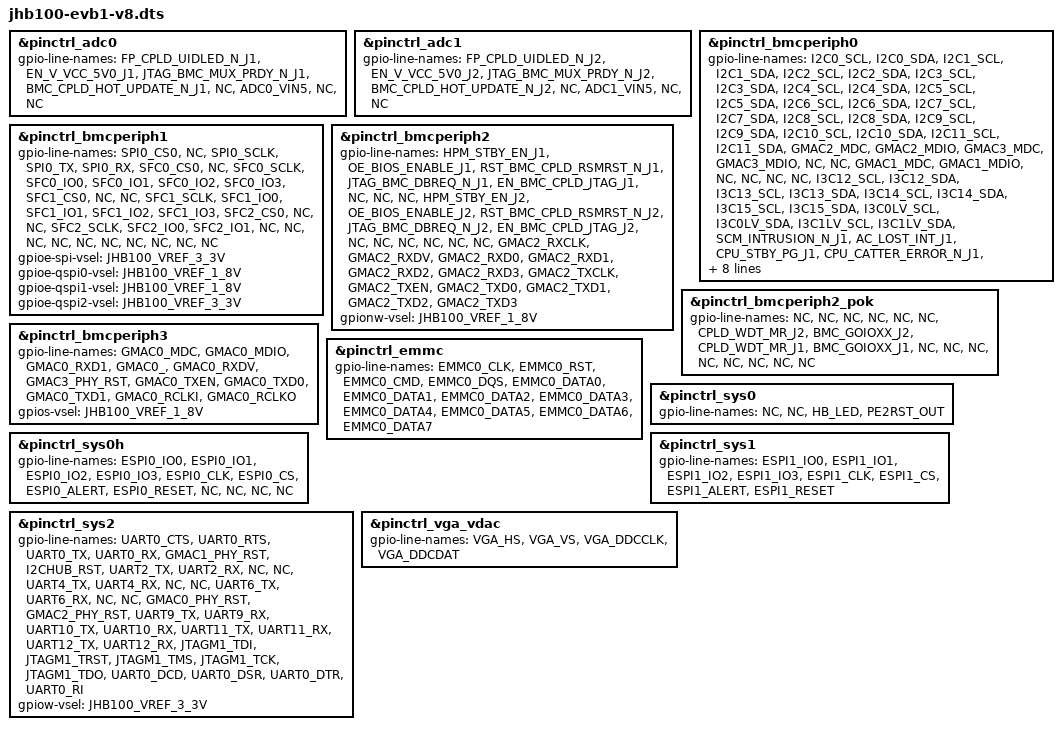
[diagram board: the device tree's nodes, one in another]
// SPDX-License-Identifier: GPL-2.0 OR MIT
/*
 * Copyright (c) 2025 StarFive Technology Co., Ltd.
 */

#include "jhb100-evb1.dtsi"
#include "jhb100-evb1-ethernet.dtsi"
#include "jhb100-evb1-sib2.dtsi"

&pinctrl_adc0 {
	gpio-line-names =
		"FP_CPLD_UIDLED_N_J1", "EN_V_VCC_5V0_J1",		/* GPIOG0-1 */
		"JTAG_BMC_MUX_PRDY_N_J1", "BMC_CPLD_HOT_UPDATE_N_J1",	/* GPIOG2-3 */
		"NC", "ADC0_VIN5", "NC", "NC";				/* GPIOG4-7 */
};

&pinctrl_adc1 {
	gpio-line-names =
		"FP_CPLD_UIDLED_N_J2", "EN_V_VCC_5V0_J2",		/* GPIOH0-1 */
		"JTAG_BMC_MUX_PRDY_N_J2", "BMC_CPLD_HOT_UPDATE_N_J2",	/* GPIOH2-3 */
		"NC", "ADC1_VIN5", "NC", "NC";				/* GPIOH4-7 */
};

&pinctrl_bmcperiph0 {
	gpio-line-names =
		"I2C0_SCL", "I2C0_SDA", "I2C1_SCL", "I2C1_SDA",			/* GPIOB0-3 */
		"I2C2_SCL", "I2C2_SDA", "I2C3_SCL", "I2C3_SDA",			/* GPIOB4-7 */
		"I2C4_SCL", "I2C4_SDA",	"I2C5_SCL", "I2C5_SDA",			/* GPIOB8-11 */
		"I2C6_SCL", "I2C6_SDA", "I2C7_SCL", "I2C7_SDA",			/* GPIOB12-15 */
		"I2C8_SCL", "I2C8_SDA", "I2C9_SCL", "I2C9_SDA",			/* GPIOB16-19 */
		"I2C10_SCL", "I2C10_SDA", "I2C11_SCL", "I2C11_SDA",		/* GPIOB20-23 */
		"GMAC2_MDC", "GMAC2_MDIO", "GMAC3_MDC", "GMAC3_MDIO",		/* GPIOB24-27 */
		"NC", "NC", "GMAC1_MDC", "GMAC1_MDIO",				/* GPIOB28-31 */
		"NC", "NC", "NC", "NC",						/* GPIOB32-35 */
		"I3C12_SCL", "I3C12_SDA", "I3C13_SCL", "I3C13_SDA",		/* GPIOB36-39 */
		"I3C14_SCL", "I3C14_SDA", "I3C15_SCL", "I3C15_SDA",		/* GPIOB40-43 */
		"I3C0LV_SCL", "I3C0LV_SDA", "I3C1LV_SCL", "I3C1LV_SDA",		/* GPIOB44-47 */
		"SCM_INTRUSION_N_J1", "AC_LOST_INT_J1",				/* GPIOB48-49 */
		"CPU_STBY_PG_J1", "CPU_CATTER_ERROR_N_J1",			/* GPIOB50-51 */
		"I3C4LV_SCL", "I3C4LV_SDA", "I3C5LV_SCL", "I3C5LV_SDA",		/* GPIOB52-55 */
		"SCM_INTRUSION_N_J2", "AC_LOST_INT_J2",				/* GPIOB56-57 */
		"CPU_STBY_PG_J2", "CPU_CATTER_ERROR_N_J2";			/* GPIOB58-59 */

	gpioe-i3c0-vsel = <JHB100_VREF_3_3V>; /* VREF for GPIOB8-11, 32-33 */
	gpioe-i3c1-vsel = <JHB100_VREF_3_3V>; /* VREF for GPIOB12-15, 34-35 */
	gpioe-i3c2-vsel = <JHB100_VREF_3_3V>; /* VREF for GPIOB16-23 */
	gpioe-i3c4-vsel = <JHB100_VREF_3_3V>; /* VREF for GPIOB36-43 */
};

&pinctrl_bmcperiph1 {
	gpio-line-names =
		"SPI0_CS0", "NC", "SPI0_SCLK", "SPI0_TX",			/* GPIOC0-3 */
		"SPI0_RX", "SFC0_CS0", "NC", "SFC0_SCLK",			/* GPIOC4-7 */
		"SFC0_IO0", "SFC0_IO1", "SFC0_IO2", "SFC0_IO3",			/* GPIOC8-11 */
		"SFC1_CS0", "NC", "NC", "SFC1_SCLK",				/* GPIOC12-15 */
		"SFC1_IO0", "SFC1_IO1", "SFC1_IO2", "SFC1_IO3",			/* GPIOC16-19 */
		"SFC2_CS0", "NC", "NC", "SFC2_SCLK",				/* GPIOC20-23 */
		"SFC2_IO0", "SFC2_IO1", "NC", "NC",				/* GPIOC24-27 */
		"NC", "NC", "NC", "NC",						/* GPIOC28-31 */
		"NC", "NC", "NC", "NC";						/* GPIOC32-35 */

	gpioe-spi-vsel = <JHB100_VREF_3_3V>; /* VREF for GPIOC0-4 */
	gpioe-qspi0-vsel = <JHB100_VREF_1_8V>; /* VREF for GPIOC5-11 */
	gpioe-qspi1-vsel = <JHB100_VREF_1_8V>; /* VREF for GPIOC12-19 */
	gpioe-qspi2-vsel = <JHB100_VREF_3_3V>; /* VREF for GPIOC20-27 */
};

&pinctrl_bmcperiph2 {
	gpio-line-names =
		"HPM_STBY_EN_J1", "OE_BIOS_ENABLE_J1",				/* GPIOD0-1 */
		"RST_BMC_CPLD_RSMRST_N_J1", "JTAG_BMC_DBREQ_N_J1",		/* GPIOD2-3 */
		"EN_BMC_CPLD_JTAG_J1", "NC", "NC", "NC",			/* GPIOD4-7 */
		"HPM_STBY_EN_J2", "OE_BIOS_ENABLE_J2",				/* GPIOD8-9 */
		"RST_BMC_CPLD_RSMRST_N_J2", "JTAG_BMC_DBREQ_N_J2",		/* GPIOD10-11 */
		"EN_BMC_CPLD_JTAG_J2", "NC", "NC", "NC",			/* GPIOD12-15 */
		"NC", "NC", "NC", "GMAC2_RXCLK",				/* GPIOD16-19 */
		"GMAC2_RXDV", "GMAC2_RXD0", "GMAC2_RXD1", "GMAC2_RXD2",		/* GPIOD20-23 */
		"GMAC2_RXD3", "GMAC2_TXCLK", "GMAC2_TXEN", "GMAC2_TXD0",	/* GPIOD24-27 */
		"GMAC2_TXD1", "GMAC2_TXD2", "GMAC2_TXD3";			/* GPIOD28-30 */

	gpionw-vsel = <JHB100_VREF_1_8V>; /* VREF for GPIOD19-30 */
};

&pinctrl_bmcperiph2_pok {
	gpio-line-names =
		"NC", "NC", "NC", "NC",				/* GPIOD31-34 */
		"NC", "NC", "CPLD_WDT_MR_J2", "BMC_GOIOXX_J2",	/* GPIOD35-38 */
		"CPLD_WDT_MR_J1", "BMC_GOIOXX_J1", "NC", "NC",	/* GPIOD39-42 */
		"NC", "NC", "NC", "NC",				/* GPIOD43-46 */
		"NC", "NC";					/* GPIOD47-48 */
};

&pinctrl_bmcperiph3 {
	gpio-line-names =
		"GMAC0_MDC", "GMAC0_MDIO", "GMAC0_RXD1", "GMAC0_",		/* GPIOE0-3 */
		"GMAC0_RXDV", "GMAC3_PHY_RST", "GMAC0_TXEN", "GMAC0_TXD0",	/* GPIOE4-7 */
		"GMAC0_TXD1", "GMAC0_RCLKI", "GMAC0_RCLKO";			/* GPIOE8-11 */

	gpios-vsel = <JHB100_VREF_1_8V>; /* VREF for GPIOE0-10 */
};

&pinctrl_emmc {
	gpio-line-names =
		"EMMC0_CLK", "EMMC0_RST", "EMMC0_CMD", "EMMC0_DQS",		/* GPIOF0-3 */
		"EMMC0_DATA0", "EMMC0_DATA1", "EMMC0_DATA2", "EMMC0_DATA3",	/* GPIOF4-7 */
		"EMMC0_DATA4", "EMMC0_DATA5", "EMMC0_DATA6", "EMMC0_DATA7";	/* GPIOF8-11 */
};

&pinctrl_sys0 {
	gpio-line-names =
		"NC", "NC", "HB_LED", "PE2RST_OUT";	/* GPIOA0-3 */
};

&pinctrl_sys0h {
	gpio-line-names =
		"ESPI0_IO0", "ESPI0_IO1", "ESPI0_IO2", "ESPI0_IO3",		/* GPIOA4-7 */
		"ESPI0_CLK", "ESPI0_CS", "ESPI0_ALERT", "ESPI0_RESET",		/* GPIOA8-11 */
		"NC", "NC", "NC", "NC";						/* GPIOA12-15 */
};

&pinctrl_sys1 {
	gpio-line-names =
		"ESPI1_IO0", "ESPI1_IO1", "ESPI1_IO2", "ESPI1_IO3",		/* GPIOA16-19 */
		"ESPI1_CLK", "ESPI1_CS", "ESPI1_ALERT", "ESPI1_RESET";		/* GPIOA20-23 */
};

&pinctrl_sys2 {
	gpio-line-names =
		"UART0_CTS", "UART0_RTS", "UART0_TX", "UART0_RX",		/* GPIOA24-27 */
		"GMAC1_PHY_RST", "I2CHUB_RST", "UART2_TX", "UART2_RX",		/* GPIOA28-31 */
		"NC", "NC", "UART4_TX", "UART4_RX",				/* GPIOA32-35 */
		"NC", "NC", "UART6_TX", "UART6_RX",				/* GPIOA36-39 */
		"NC", "NC", "GMAC0_PHY_RST", "GMAC2_PHY_RST",			/* GPIOA40-43 */
		"UART9_TX", "UART9_RX", "UART10_TX", "UART10_RX",		/* GPIOA44-47 */
		"UART11_TX", "UART11_RX", "UART12_TX", "UART12_RX",		/* GPIOA48-51 */
		"JTAGM1_TDI", "JTAGM1_TRST", "JTAGM1_TMS", "JTAGM1_TCK",	/* GPIOA52-55 */
		"JTAGM1_TDO", "UART0_DCD", "UART0_DSR", "UART0_DTR",		/* GPIOA56-59 */
		"UART0_RI";							/* GPIOA60 */

	gpiow-vsel = <JHB100_VREF_3_3V>; /* VREF for GPIOA36-43 */
};

&pinctrl_vga_vdac {
	gpio-line-names =
		"VGA_HS", "VGA_VS", "VGA_DDCCLK", "VGA_DDCDAT";		/* GPIOI0-3 */
};

